VERSION ""

NS_ :

BS_:

BU_: CAN_IO_2

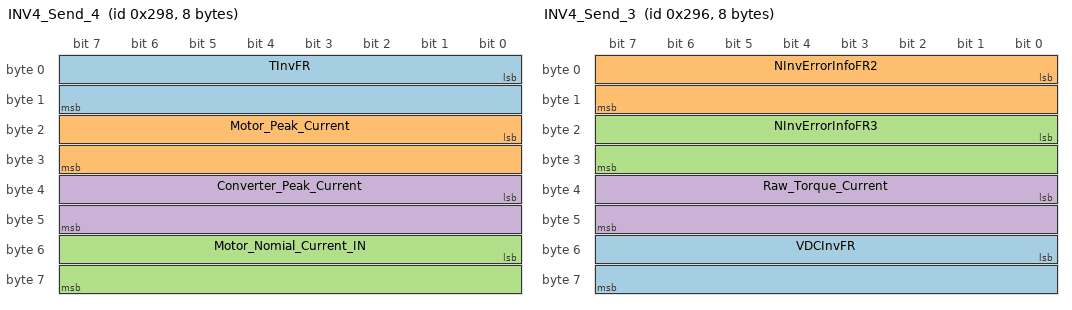
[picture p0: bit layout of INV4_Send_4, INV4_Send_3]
BO_ 664 INV4_Send_4: 8 Vector__XXX
 SG_ TInvFR : 0|16@1- (0.1,-0) [-3276.8|3276.7] "degree"  CAN_IO_2
 SG_ Motor_Peak_Current : 16|16@1- (1,0) [-32768|32767] "A"  CAN_IO_2
 SG_ Motor_Nomial_Current_IN : 48|16@1- (1,0) [-32768|32767] "A"  CAN_IO_2
 SG_ Converter_Peak_Current : 32|16@1- (1,0) [-32768|32767] "A"  CAN_IO_2

BO_ 662 INV4_Send_3: 8 Vector__XXX
 SG_ VDCInvFR : 48|16@1- (1,0) [-32768|32767] "V"  CAN_IO_2
 SG_ NInvErrorInfoFR2 : 0|16@1- (1,0) [-32768|32767] ""  CAN_IO_2
 SG_ NInvErrorInfoFR3 : 16|16@1- (1,0) [-32768|32767] ""  CAN_IO_2
 SG_ Raw_Torque_Current : 32|16@1- (1,0) [-32768|32767] "A"  CAN_IO_2

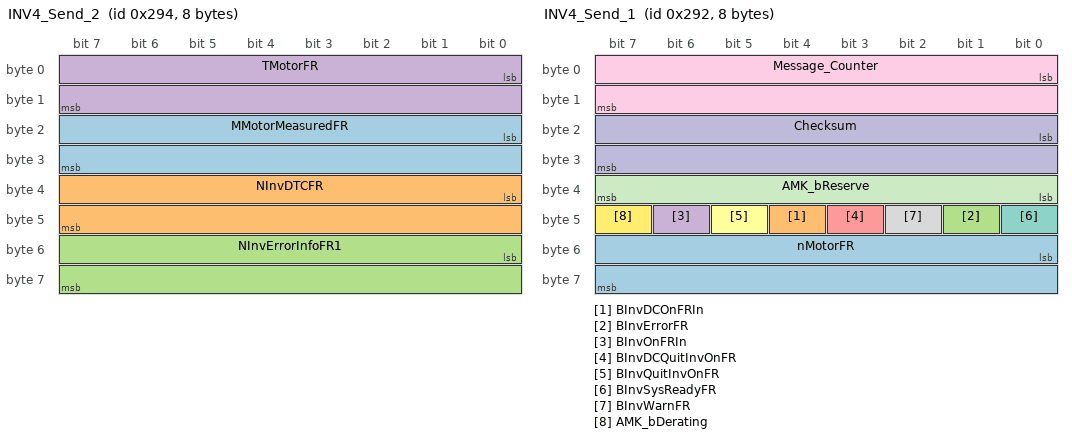
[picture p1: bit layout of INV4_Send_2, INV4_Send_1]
BO_ 660 INV4_Send_2: 8 Vector__XXX
 SG_ MMotorMeasuredFR : 16|16@1- (1,0) [-32768|32767] ""  CAN_IO_2
 SG_ NInvDTCFR : 32|16@1- (1,0) [-32768|32767] ""  CAN_IO_2
 SG_ NInvErrorInfoFR1 : 48|16@1- (1,0) [-32768|32767] ""  CAN_IO_2
 SG_ TMotorFR : 0|16@1- (0.1,-0) [-3276.8|3276.7] "degrees"  CAN_IO_2

BO_ 658 INV4_Send_1: 8 Vector__XXX
 SG_ nMotorFR : 48|16@1- (1,0) [-32768|32767] "rpm"  CAN_IO_2
 SG_ BInvDCOnFRIn : 44|1@1+ (1,0) [0|1] ""  CAN_IO_2
 SG_ BInvErrorFR : 41|1@1+ (1,0) [0|1] ""  CAN_IO_2
 SG_ BInvOnFRIn : 46|1@1+ (1,0) [0|1] ""  CAN_IO_2
 SG_ BInvDCQuitInvOnFR : 43|1@1+ (1,0) [0|1] ""  CAN_IO_2
 SG_ BInvQuitInvOnFR : 45|1@1+ (1,0) [0|1] ""  CAN_IO_2
 SG_ BInvSysReadyFR : 40|1@1+ (1,0) [0|1] ""  CAN_IO_2
 SG_ BInvWarnFR : 42|1@1+ (1,0) [0|1] ""  CAN_IO_2
 SG_ Message_Counter : 0|16@1+ (1,0) [0|65535] ""  CAN_IO_2
 SG_ Checksum : 16|16@1+ (1,0) [0|65535] ""  CAN_IO_2
 SG_ AMK_bReserve : 32|8@1- (1,0) [-128|127] ""  CAN_IO_2
 SG_ AMK_bDerating : 47|1@1+ (1,0) [0|1] ""  CAN_IO_2

BO_ 391 INV4_Receive_1: 8 CAN_IO_2
 SG_ BInvDCOnFROut : 9|1@1+ (1,0) [0|1] "" Vector__XXX
 SG_ BInvEnableFR : 10|1@1+ (1,0) [0|1] "" Vector__XXX
 SG_ BInvErrorResetFR : 11|1@1+ (1,0) [0|1] "" Vector__XXX
 SG_ BInvOnFROut : 8|1@1+ (1,0) [0|1] "" Vector__XXX
 SG_ MTorqueLimitNegativeFR : 48|16@1- (0.1,-0) [-3276.8|3276.7] "rpm" Vector__XXX
 SG_ MTorqueLimitPositiveFR : 32|16@1- (0.1,-0) [-3276.8|3276.7] "" Vector__XXX
 SG_ MInvFRFinal : 16|16@1- (0.1,-0) [-3276.8|3276.7] "" Vector__XXX
 SG_ AMK_bReserve : 12|8@1- (1,0) [-128|127] "" Vector__XXX

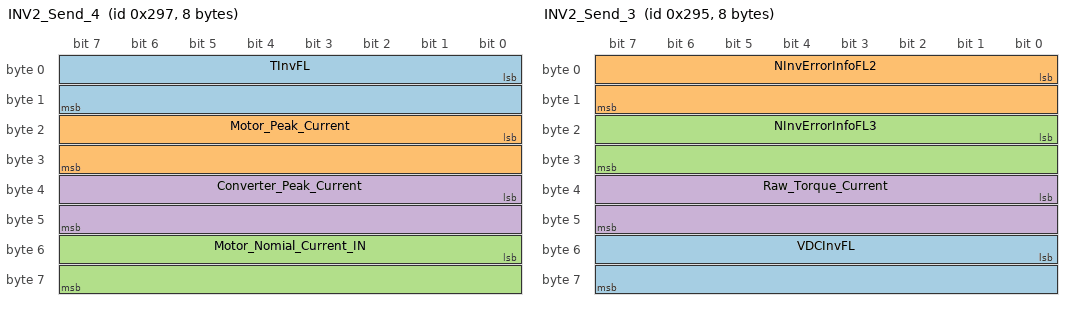
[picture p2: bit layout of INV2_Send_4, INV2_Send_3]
BO_ 663 INV2_Send_4: 8 Vector__XXX
 SG_ TInvFL : 0|16@1- (0.1,-0) [-3276.8|3276.7] "degree"  CAN_IO_2
 SG_ Motor_Peak_Current : 16|16@1- (1,0) [-32768|32767] "A"  CAN_IO_2
 SG_ Motor_Nomial_Current_IN : 48|16@1- (1,0) [-32768|32767] "A"  CAN_IO_2
 SG_ Converter_Peak_Current : 32|16@1- (1,0) [-32768|32767] "A"  CAN_IO_2

BO_ 661 INV2_Send_3: 8 Vector__XXX
 SG_ VDCInvFL : 48|16@1- (1,0) [-32768|32767] "V"  CAN_IO_2
 SG_ NInvErrorInfoFL2 : 0|16@1- (1,0) [-32768|32767] ""  CAN_IO_2
 SG_ NInvErrorInfoFL3 : 16|16@1- (1,0) [-32768|32767] ""  CAN_IO_2
 SG_ Raw_Torque_Current : 32|16@1- (1,0) [-32768|32767] "A"  CAN_IO_2

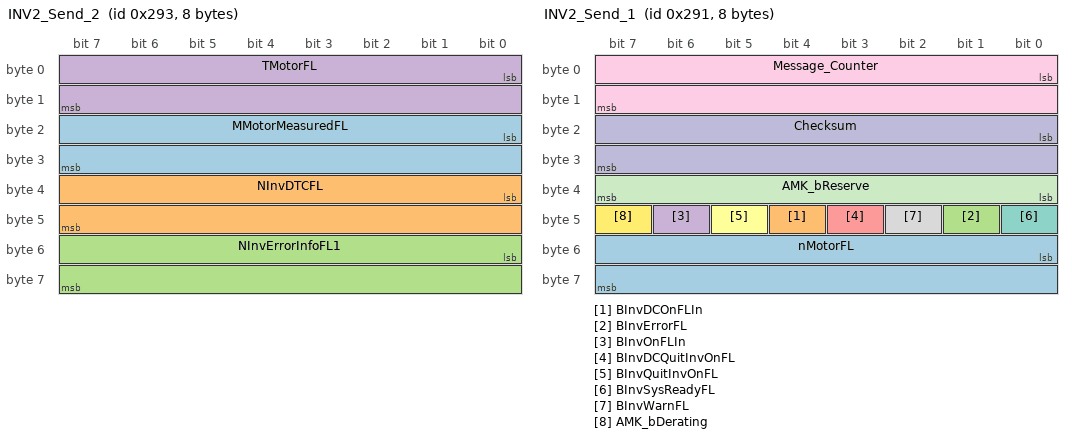
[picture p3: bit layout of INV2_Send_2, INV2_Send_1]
BO_ 659 INV2_Send_2: 8 Vector__XXX
 SG_ MMotorMeasuredFL : 16|16@1- (1,0) [-32768|32767] ""  CAN_IO_2
 SG_ NInvDTCFL : 32|16@1- (1,0) [-32768|32767] ""  CAN_IO_2
 SG_ NInvErrorInfoFL1 : 48|16@1- (1,0) [-32768|32767] ""  CAN_IO_2
 SG_ TMotorFL : 0|16@1- (0.1,-0) [-3276.8|3276.7] "degrees"  CAN_IO_2

BO_ 657 INV2_Send_1: 8 Vector__XXX
 SG_ nMotorFL : 48|16@1- (1,0) [-32768|32767] "rpm"  CAN_IO_2
 SG_ BInvDCOnFLIn : 44|1@1+ (1,0) [0|1] ""  CAN_IO_2
 SG_ BInvErrorFL : 41|1@1+ (1,0) [0|1] ""  CAN_IO_2
 SG_ BInvOnFLIn : 46|1@1+ (1,0) [0|1] ""  CAN_IO_2
 SG_ BInvDCQuitInvOnFL : 43|1@1+ (1,0) [0|1] ""  CAN_IO_2
 SG_ BInvQuitInvOnFL : 45|1@1+ (1,0) [0|1] ""  CAN_IO_2
 SG_ BInvSysReadyFL : 40|1@1+ (1,0) [0|1] ""  CAN_IO_2
 SG_ BInvWarnFL : 42|1@1+ (1,0) [0|1] ""  CAN_IO_2
 SG_ Message_Counter : 0|16@1+ (1,0) [0|65535] ""  CAN_IO_2
 SG_ Checksum : 16|16@1+ (1,0) [0|65535] ""  CAN_IO_2
 SG_ AMK_bReserve : 32|8@1- (1,0) [-128|127] ""  CAN_IO_2
 SG_ AMK_bDerating : 47|1@1+ (1,0) [0|1] ""  CAN_IO_2

BO_ 390 INV2_Receive_1: 8 CAN_IO_2
 SG_ BInvDCOnFLOut : 9|1@1+ (1,0) [0|1] "" Vector__XXX
 SG_ BInvEnableFL : 10|1@1+ (1,0) [0|1] "" Vector__XXX
 SG_ BInvErrorResetFL : 11|1@1+ (1,0) [0|1] "" Vector__XXX
 SG_ BInvOnFLOut : 8|1@1+ (1,0) [0|1] "" Vector__XXX
 SG_ MTorqueLimitNegativeFL : 48|16@1- (0.1,-0) [-3276.8|3276.7] "rpm" Vector__XXX
 SG_ MTorqueLimitPositiveFL : 32|16@1- (0.1,-0) [-3276.8|3276.7] "" Vector__XXX
 SG_ MInvFLFinal : 16|16@1- (0.1,-0) [-3276.8|3276.7] "" Vector__XXX
 SG_ AMK_bReserve : 12|8@1- (1,0) [-128|127] "" Vector__XXX

BA_DEF_ BO_  "CANFD_BRS" ENUM  "0","1";
BA_DEF_ BO_  "VFrameFormat" ENUM  "StandardCAN","ExtendedCAN","reserved","reserved","reserved","reserved","reserved","reserved","reserved","reserved","reserved","reserved","reserved","reserved","StandardCAN_FD","ExtendedCAN_FD";
BA_DEF_ BO_  "GenMsgCycleTime" INT 0 3600000;
BA_DEF_  "BusType" STRING ;
BA_DEF_DEF_  "CANFD_BRS" "0";
BA_DEF_DEF_  "VFrameFormat" "StandardCAN";
BA_DEF_DEF_  "GenMsgCycleTime" 0;
BA_DEF_DEF_  "BusType" "CAN";
BA_ "GenMsgCycleTime" BO_ 664 20;
BA_ "GenMsgCycleTime" BO_ 662 20;
BA_ "GenMsgCycleTime" BO_ 660 20;
BA_ "GenMsgCycleTime" BO_ 658 5;
BA_ "GenMsgCycleTime" BO_ 391 1;
BA_ "GenMsgCycleTime" BO_ 663 20;
BA_ "GenMsgCycleTime" BO_ 661 20;
BA_ "GenMsgCycleTime" BO_ 659 20;
BA_ "GenMsgCycleTime" BO_ 657 5;
BA_ "GenMsgCycleTime" BO_ 390 1;
